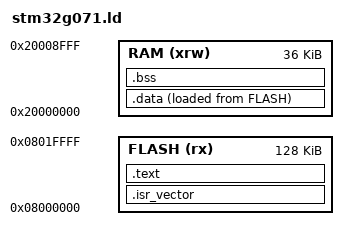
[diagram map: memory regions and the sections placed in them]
/* Entry Point */
ENTRY(Reset_Handler)

/* Highest address of the user mode stack */
_estack = ORIGIN(RAM) + LENGTH(RAM);	/* end of "RAM" Ram type memory */

/* Memories definition */
MEMORY
{
  RAM    (xrw)    : ORIGIN = 0x20000000,   LENGTH = 36K
  FLASH    (rx)    : ORIGIN = 0x8000000,   LENGTH = 128K
}

SECTIONS
{

.isr_vector :
  {
    *(.isr_vector)
    . = ALIGN(4);
  }> FLASH

  .text :
  {
    *(.text)
    *(.text.*)
    *(.init)
    *(.fini)
    *(.rodata)
    *(.rodata.*)
    . = ALIGN(4);
    _etext = .;
  }> FLASH

 /* Used by the startup to initialize data */
  _sidata = LOADADDR(.data);

  .data :
  {
    _sdata = .;
    *(.data)
    *(.data.*)
    . = ALIGN(4);
    _edata = .;
  }> RAM AT> FLASH

  .bss :
  {
    _sbss = .;
    __bss_start__ = _sbss;
    *(.bss)
    *(.bss.*)
    *(COMMON)
    . = ALIGN(4);
    _ebss = .;
    __bss_end__ = _ebss;
     . = ALIGN(4);
    end = .;
    __end__ = .;
  }> RAM
}
